# ISS_CBUFF register map
Vendor: Texas Instruments
Peripheral module from a debugger description file (folder omap5430_ES2_PUBLIC).
Registers are 32-bit, access per field, reset 0x0 unless marked. A register's access mark holds for its fields unless they carry their own. Offsets are as the file gives them; lines under a group give offsets from that group; [hi:lo] are bit positions; {n}, {i} and the like mark numbered series; 'fields as' and 'values as' point back to an identical list; <NAME> marks a mode.

## ISS_CBUFF
0x00 CBUFF_HL_REVISION ro reset not defined — IP revision identifier (X.Y.R) Used by software to track features, bugs, and compatibility
  [31:0] REVISION — IP Revision
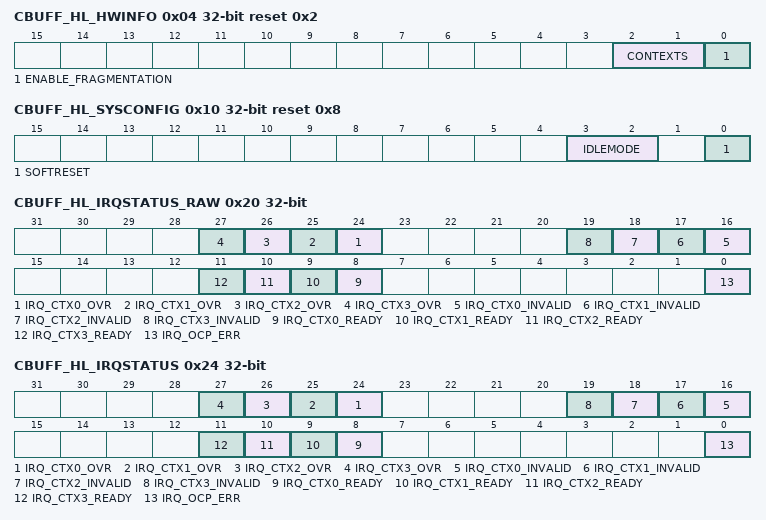
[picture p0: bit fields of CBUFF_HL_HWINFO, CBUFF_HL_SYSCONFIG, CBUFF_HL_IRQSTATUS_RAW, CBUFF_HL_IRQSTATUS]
0x04 CBUFF_HL_HWINFO ro reset 0x2 — Information about the IP module's hardware configuration.
  [2:1] CONTEXTS — Number of contexts
    3=RSV (Reserved); 2=EIGHT (8 contexts); 1=FOUR (4 contexts); 0=TWO (2 contexts)
  [0] ENABLE_FRAGMENTATION — Provides information to software if fragmentation support is available
    1=ONE (Yes); 0=ZERO (No)
0x10 CBUFF_HL_SYSCONFIG reset 0x8 — Clock management configuration
  [3:2] IDLEMODE rw — Configuration of the local target state management mode. By definition, target can handle read/write transaction as long as it is out of IDLE state.
    0=Force-idle mode: local target's idle state follows (acknowledges) the system's idle requests unconditionally, that is, regardless of the IP module's internal requirements. Backup mode, for debug only.; 1=no (No-idle mode: local target never enters IDLE state. Backup mode, for debug only.); 3=smartwakeup (Reserved); 2=Smart-idle mode: local target's IDLE state eventually follows (acknowledges) the system's IDLE requests, depending on the IP module's internal requirements. IP module must not generate (IRQ- or DMA-request-related) wake-up events.
  [0] SOFTRESET rw — Software reset
    0=done (No action); 1=pending (Initiate software reset); 1=pending (Reset (software or other) ongoing); 0=Reset_done,_no_pending_action
0x20 CBUFF_HL_IRQSTATUS_RAW access not given — Per-event raw interrupt status vector. Raw status is set even if event is not enabled. Write 1 to set the (raw) status, mostly for debug.
  [all] fields
    0=noevent (No action); 1=pending (Set event (debug)); 1=pending (Event pending); 0=No_event_pending
  [n+24] IRQ_CTX{n}_OVR (n=0..3) — Buffer overflow event. (access RW W1toSet)
  [n+16] IRQ_CTX{n}_INVALID (n=0..3) — Invalid access. (access RW W1toSet)
  [n+8] IRQ_CTX{n}_READY (n=0..3) — The WB physical window is ready to be accessed by the CPU. (access RW W1toSet)
  [0] IRQ_OCP_ERR — OCP error received in the master port. (access RW W1toSet)
0x24 CBUFF_HL_IRQSTATUS access not given — Per-event 'enabled' interrupt status vector. Enabled status is not set unless event is enabled. Write 1 to clear the status after interrupt has been serviced (raw status gets cleared, that is, even if not enabled).
  [all] fields
    0=noaction; 1=Clear (raw) event; 1=pending (Event pending); 0=noevent (No (enabled) event pending)
  [n+24] IRQ_CTX{n}_OVR (n=0..3) — Buffer overflow event. Check the functional specification for more details. (access RW W1toClr)
  [n+16] IRQ_CTX{n}_INVALID (n=0..3) — Invalid access. Check the functional specification for more details. (access RW W1toClr)
  [n+8] IRQ_CTX{n}_READY (n=0..3) — The WB physical window is ready to be accessed by the CPU. Check the functional specification for more details. (access RW W1toClr)
  [0] IRQ_OCP_ERR — OCP error received in the master port. (access RW W1toClr)
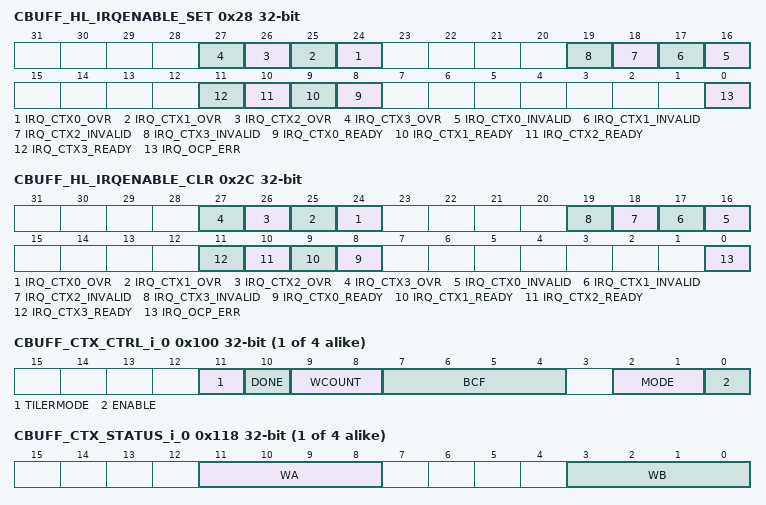
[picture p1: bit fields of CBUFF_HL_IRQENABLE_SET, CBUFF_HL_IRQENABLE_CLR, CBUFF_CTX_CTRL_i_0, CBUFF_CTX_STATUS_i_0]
0x28 CBUFF_HL_IRQENABLE_SET access not given — Per-event interrupt enable bit vector. Write 1 to set (enable interrupt). Readout equal to corresponding _CLR register.
  [all] fields
    0=noaction; 1=Enable interrupt; 1=enabled (Interrupt enabled); 0=disabled (Interrupt disabled (masked))
  [n+24] IRQ_CTX{n}_OVR (n=0..3) — Buffer overflow event. Check the functional specification for more details. (access RW W1toSet)
  [n+16] IRQ_CTX{n}_INVALID (n=0..3) — Invalid access. Check the functional specification for more details. (access RW W1toSet)
  [n+8] IRQ_CTX{n}_READY (n=0..3) — The WB physical window is ready to be accessed by the CPU. Check the functional specification for more details. (access RW W1toSet)
  [0] IRQ_OCP_ERR — OCP error received in the master port. (access RW W1toSet)
0x2C CBUFF_HL_IRQENABLE_CLR access not given — Per-event interrupt enable bit vector, line 0. Write 1 to clear (disable interrupt). Readout equal to corresponding _SET register.
  [all] fields
    0=noaction; 1=Disable interrupt; 1=enabled (Interrupt enabled); 0=disabled (Interrupt disabled (masked))
  [n+24] IRQ_CTX{n}_OVR (n=0..3) — Buffer overflow event. Check the functional specification for more details. (access RW W1toClr)
  [n+16] IRQ_CTX{n}_INVALID (n=0..3) — Invalid access. Check the functional specification for more details. (access RW W1toClr)
  [n+8] IRQ_CTX{n}_READY (n=0..3) — The WB physical window is ready to be accessed by the CPU. Check the functional specification for more details. (access RW W1toClr)
  [0] IRQ_OCP_ERR — OCP error received in the master port. (access RW W1toClr)
{0x100+0x20*i} CBUFF_CTX_CTRL_i_{i} (i=0..3) — Context control register
  [11] TILERMODE rw — Sets the expected value for ADDR[32]. If ADDR[32]=TILERMODE, ADDR[31:4] is processed and eventually translated. Otherwise, the access is handled as transparent, regardless of the other address bits.
  [10] DONE wo — Write this bit to 1 to indicate the CPU has finished processing its physical buffer. This bit is automatically cleared by hardware, reads always return 0. This bit has no effect when MODE=2 (read/write)
    0=ZERO (No effect.); 1=ONE (The CPU has completely processed the WB physical buffer.)
  [9:8] WCOUNT rw — Window count
    0=W2 (2 windows); 1=W4 (4 windows); 3=W16 (16 windows); 2=W8 (8 windows)
  [7:4] BCF rw — This register controls the bandwidth control feedback loop output. 0: Control loop disabled. 1-15: The control feedback loop enabled. Behavior depends on functional mode, see , .
  [2:1] MODE rw — Selects the functional mode of this context
    0=WRITE (Write mode. ISS writes and CPU reads the physical space. CPU accesses are out of the scope of the CBUFF module; therefore, only writes are permitted between and .); 1=READ (Read mode. Hardware reads and CPU writes the physical space. CPU accesses are out of the scope of the CBUFF module; therefore, only reads are permitted between and .); 2=RWMODE (Read/Write mode. Read and writes are monitored by the CBUFF. WB is used to track current read positions WA is used to track current write position.)
  [0] ENABLE rw — Enable/disable
    0=DI (Disables the context. This resets the internal state of the context. All accesses received on OCPI are transmitted to OCPO without modification. Disabling the context takes effect immediately. Software must ensure that no more accesses to the context are outstanding before disabling it. Otherwise memory corruption may occur.); 1=EN (Enable the context. All accesses between and are processed by the CBUFF.)
{0x104+0x20*i} CBUFF_CTX_START_i_{i} (i=0..3) — Start address of the virtual space managed by the context
  [31:4] ADDR rw — Address, in 128-bit words
{0x108+0x20*i} CBUFF_CTX_END_i_{i} (i=0..3) — End address of the virtual space managed by the context
  [31:4] ADDR rw — Address, in 128-bit words
{0x10C+0x20*i} CBUFF_CTX_WINDOWSIZE_i_{i} (i=0..3) — Defines the size of a window
  [23:4] SIZE rw — Size, in 128-bit words
{0x110+0x20*i} CBUFF_CTX_THRESHOLD_F_i_{i} (i=0..3) — Threshold value used to check if a write window is full
  [23:0] THRESHOLD rw — Threshold value, in bytes
{0x114+0x20*i} CBUFF_CTX_THRESHOLD_S_i_{i} (i=0..3) — Threshold value used to control the BCF synchronization mechanism
  [23:0] THRESHOLD rw — Threshold value, in bytes
{0x118+0x20*i} CBUFF_CTX_STATUS_i_{i} ro (i=0..3) — Status register
  [11:8] WA — Valid values depend on theCBUFF_CTX_CTRL_i[9:8] WCOUNT bit field.
  [3:0] WB — Valid values depend on the CBUFF_CTX_CTRL_I[9:8] WCOUNT bit field.
{0x11C+0x20*i} CBUFF_CTX_PHY_i_{i} (i=0..3) — Start address of the first physical buffer managed by the context when fragmentation support is disabled.
  [31:4] ADDR rw — Address, in 128 bit words.
